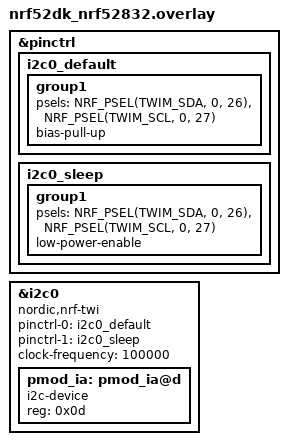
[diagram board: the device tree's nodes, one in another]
&pinctrl {
    i2c0_default: i2c0_default {
        group1 {
            psels = <NRF_PSEL(TWIM_SDA, 0, 26)>,
                    <NRF_PSEL(TWIM_SCL, 0, 27)>;
            bias-pull-up;    /* Enable internal pull-ups */
        };
    };

    i2c0_sleep: i2c0_sleep {
        group1 {
            psels = <NRF_PSEL(TWIM_SDA, 0, 26)>,
                    <NRF_PSEL(TWIM_SCL, 0, 27)>;
            low-power-enable;
        };
    };
};

&i2c0 {
    compatible = "nordic,nrf-twi";
    status = "okay";
    pinctrl-0 = <&i2c0_default>;
    pinctrl-1 = <&i2c0_sleep>;
    pinctrl-names = "default", "sleep";
    clock-frequency = <100000>;    /* Changed to numeric value instead of define */

    pmod_ia: pmod_ia@d {
        compatible = "i2c-device";
        reg = <0x0d>;
    };
};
